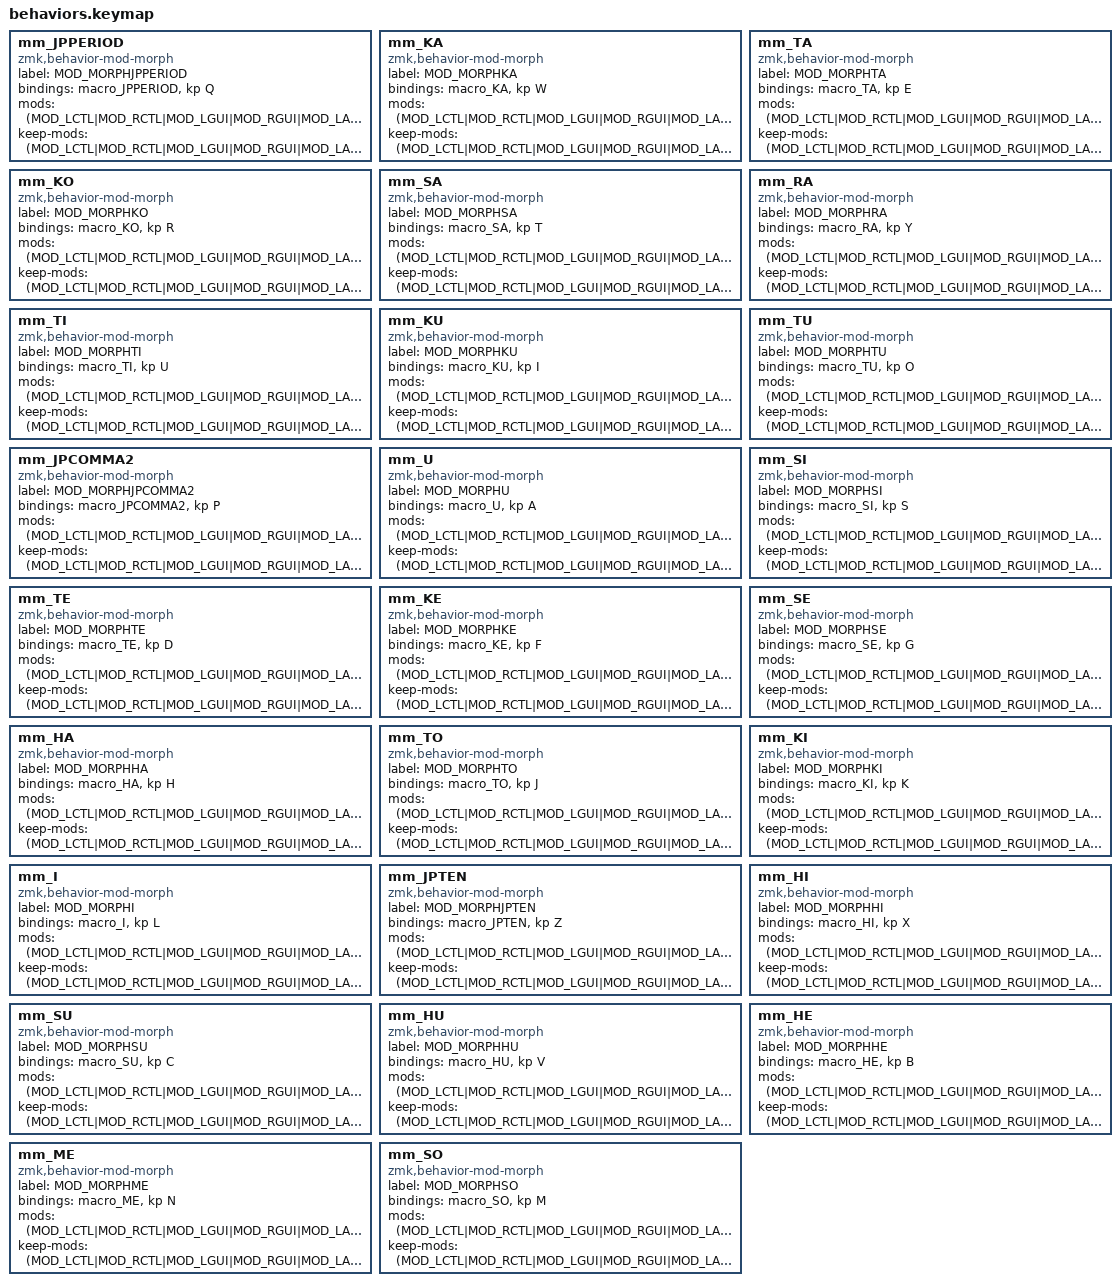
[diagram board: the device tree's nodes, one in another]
mm_JPPERIOD: mm_JPPERIOD{
compatible = "zmk,behavior-mod-morph";
label = "MOD_MORPHJPPERIOD";
#binding-cells = <0>;
bindings = <&macro_JPPERIOD>, <&kp Q>;
mods = <(MOD_LCTL|MOD_RCTL|MOD_LGUI|MOD_RGUI|MOD_LALT|MOD_RALT)>;
keep-mods = <(MOD_LCTL|MOD_RCTL|MOD_LGUI|MOD_RGUI|MOD_LALT)>;
};

mm_KA: mm_KA{
compatible = "zmk,behavior-mod-morph";
label = "MOD_MORPHKA";
#binding-cells = <0>;
bindings = <&macro_KA>, <&kp W>;
mods = <(MOD_LCTL|MOD_RCTL|MOD_LGUI|MOD_RGUI|MOD_LALT|MOD_RALT)>;
keep-mods = <(MOD_LCTL|MOD_RCTL|MOD_LGUI|MOD_RGUI|MOD_LALT)>;
};

mm_TA: mm_TA{
compatible = "zmk,behavior-mod-morph";
label = "MOD_MORPHTA";
#binding-cells = <0>;
bindings = <&macro_TA>, <&kp E>;
mods = <(MOD_LCTL|MOD_RCTL|MOD_LGUI|MOD_RGUI|MOD_LALT|MOD_RALT)>;
keep-mods = <(MOD_LCTL|MOD_RCTL|MOD_LGUI|MOD_RGUI|MOD_LALT)>;
};

mm_KO: mm_KO{
compatible = "zmk,behavior-mod-morph";
label = "MOD_MORPHKO";
#binding-cells = <0>;
bindings = <&macro_KO>, <&kp R>;
mods = <(MOD_LCTL|MOD_RCTL|MOD_LGUI|MOD_RGUI|MOD_LALT|MOD_RALT)>;
keep-mods = <(MOD_LCTL|MOD_RCTL|MOD_LGUI|MOD_RGUI|MOD_LALT)>;
};

mm_SA: mm_SA{
compatible = "zmk,behavior-mod-morph";
label = "MOD_MORPHSA";
#binding-cells = <0>;
bindings = <&macro_SA>, <&kp T>;
mods = <(MOD_LCTL|MOD_RCTL|MOD_LGUI|MOD_RGUI|MOD_LALT|MOD_RALT)>;
keep-mods = <(MOD_LCTL|MOD_RCTL|MOD_LGUI|MOD_RGUI|MOD_LALT)>;
};

mm_RA: mm_RA{
compatible = "zmk,behavior-mod-morph";
label = "MOD_MORPHRA";
#binding-cells = <0>;
bindings = <&macro_RA>, <&kp Y>;
mods = <(MOD_LCTL|MOD_RCTL|MOD_LGUI|MOD_RGUI|MOD_LALT|MOD_RALT)>;
keep-mods = <(MOD_LCTL|MOD_RCTL|MOD_LGUI|MOD_RGUI|MOD_LALT)>;
};

mm_TI: mm_TI{
compatible = "zmk,behavior-mod-morph";
label = "MOD_MORPHTI";
#binding-cells = <0>;
bindings = <&macro_TI>, <&kp U>;
mods = <(MOD_LCTL|MOD_RCTL|MOD_LGUI|MOD_RGUI|MOD_LALT|MOD_RALT)>;
keep-mods = <(MOD_LCTL|MOD_RCTL|MOD_LGUI|MOD_RGUI|MOD_LALT)>;
};

mm_KU: mm_KU{
compatible = "zmk,behavior-mod-morph";
label = "MOD_MORPHKU";
#binding-cells = <0>;
bindings = <&macro_KU>, <&kp I>;
mods = <(MOD_LCTL|MOD_RCTL|MOD_LGUI|MOD_RGUI|MOD_LALT|MOD_RALT)>;
keep-mods = <(MOD_LCTL|MOD_RCTL|MOD_LGUI|MOD_RGUI|MOD_LALT)>;
};

mm_TU: mm_TU{
compatible = "zmk,behavior-mod-morph";
label = "MOD_MORPHTU";
#binding-cells = <0>;
bindings = <&macro_TU>, <&kp O>;
mods = <(MOD_LCTL|MOD_RCTL|MOD_LGUI|MOD_RGUI|MOD_LALT|MOD_RALT)>;
keep-mods = <(MOD_LCTL|MOD_RCTL|MOD_LGUI|MOD_RGUI|MOD_LALT)>;
};

mm_JPCOMMA2: mm_JPCOMMA2{
compatible = "zmk,behavior-mod-morph";
label = "MOD_MORPHJPCOMMA2";
#binding-cells = <0>;
bindings = <&macro_JPCOMMA2>, <&kp P>;
mods = <(MOD_LCTL|MOD_RCTL|MOD_LGUI|MOD_RGUI|MOD_LALT|MOD_RALT)>;
keep-mods = <(MOD_LCTL|MOD_RCTL|MOD_LGUI|MOD_RGUI|MOD_LALT)>;
};

mm_U: mm_U{
compatible = "zmk,behavior-mod-morph";
label = "MOD_MORPHU";
#binding-cells = <0>;
bindings = <&macro_U>, <&kp A>;
mods = <(MOD_LCTL|MOD_RCTL|MOD_LGUI|MOD_RGUI|MOD_LALT|MOD_RALT)>;
keep-mods = <(MOD_LCTL|MOD_RCTL|MOD_LGUI|MOD_RGUI|MOD_LALT)>;
};

mm_SI: mm_SI{
compatible = "zmk,behavior-mod-morph";
label = "MOD_MORPHSI";
#binding-cells = <0>;
bindings = <&macro_SI>, <&kp S>;
mods = <(MOD_LCTL|MOD_RCTL|MOD_LGUI|MOD_RGUI|MOD_LALT|MOD_RALT)>;
keep-mods = <(MOD_LCTL|MOD_RCTL|MOD_LGUI|MOD_RGUI|MOD_LALT)>;
};

mm_TE: mm_TE{
compatible = "zmk,behavior-mod-morph";
label = "MOD_MORPHTE";
#binding-cells = <0>;
bindings = <&macro_TE>, <&kp D>;
mods = <(MOD_LCTL|MOD_RCTL|MOD_LGUI|MOD_RGUI|MOD_LALT|MOD_RALT)>;
keep-mods = <(MOD_LCTL|MOD_RCTL|MOD_LGUI|MOD_RGUI|MOD_LALT)>;
};

mm_KE: mm_KE{
compatible = "zmk,behavior-mod-morph";
label = "MOD_MORPHKE";
#binding-cells = <0>;
bindings = <&macro_KE>, <&kp F>;
mods = <(MOD_LCTL|MOD_RCTL|MOD_LGUI|MOD_RGUI|MOD_LALT|MOD_RALT)>;
keep-mods = <(MOD_LCTL|MOD_RCTL|MOD_LGUI|MOD_RGUI|MOD_LALT)>;
};

mm_SE: mm_SE{
compatible = "zmk,behavior-mod-morph";
label = "MOD_MORPHSE";
#binding-cells = <0>;
bindings = <&macro_SE>, <&kp G>;
mods = <(MOD_LCTL|MOD_RCTL|MOD_LGUI|MOD_RGUI|MOD_LALT|MOD_RALT)>;
keep-mods = <(MOD_LCTL|MOD_RCTL|MOD_LGUI|MOD_RGUI|MOD_LALT)>;
};

mm_HA: mm_HA{
compatible = "zmk,behavior-mod-morph";
label = "MOD_MORPHHA";
#binding-cells = <0>;
bindings = <&macro_HA>, <&kp H>;
mods = <(MOD_LCTL|MOD_RCTL|MOD_LGUI|MOD_RGUI|MOD_LALT|MOD_RALT)>;
keep-mods = <(MOD_LCTL|MOD_RCTL|MOD_LGUI|MOD_RGUI|MOD_LALT)>;
};

mm_TO: mm_TO{
compatible = "zmk,behavior-mod-morph";
label = "MOD_MORPHTO";
#binding-cells = <0>;
bindings = <&macro_TO>, <&kp J>;
mods = <(MOD_LCTL|MOD_RCTL|MOD_LGUI|MOD_RGUI|MOD_LALT|MOD_RALT)>;
keep-mods = <(MOD_LCTL|MOD_RCTL|MOD_LGUI|MOD_RGUI|MOD_LALT)>;
};

mm_KI: mm_KI{
compatible = "zmk,behavior-mod-morph";
label = "MOD_MORPHKI";
#binding-cells = <0>;
bindings = <&macro_KI>, <&kp K>;
mods = <(MOD_LCTL|MOD_RCTL|MOD_LGUI|MOD_RGUI|MOD_LALT|MOD_RALT)>;
keep-mods = <(MOD_LCTL|MOD_RCTL|MOD_LGUI|MOD_RGUI|MOD_LALT)>;
};

mm_I: mm_I{
compatible = "zmk,behavior-mod-morph";
label = "MOD_MORPHI";
#binding-cells = <0>;
bindings = <&macro_I>, <&kp L>;
mods = <(MOD_LCTL|MOD_RCTL|MOD_LGUI|MOD_RGUI|MOD_LALT|MOD_RALT)>;
keep-mods = <(MOD_LCTL|MOD_RCTL|MOD_LGUI|MOD_RGUI|MOD_LALT)>;
};

mm_JPTEN: mm_JPTEN{
compatible = "zmk,behavior-mod-morph";
label = "MOD_MORPHJPTEN";
#binding-cells = <0>;
bindings = <&macro_JPTEN>, <&kp Z>;
mods = <(MOD_LCTL|MOD_RCTL|MOD_LGUI|MOD_RGUI|MOD_LALT|MOD_RALT)>;
keep-mods = <(MOD_LCTL|MOD_RCTL|MOD_LGUI|MOD_RGUI|MOD_LALT)>;
};

mm_HI: mm_HI{
compatible = "zmk,behavior-mod-morph";
label = "MOD_MORPHHI";
#binding-cells = <0>;
bindings = <&macro_HI>, <&kp X>;
mods = <(MOD_LCTL|MOD_RCTL|MOD_LGUI|MOD_RGUI|MOD_LALT|MOD_RALT)>;
keep-mods = <(MOD_LCTL|MOD_RCTL|MOD_LGUI|MOD_RGUI|MOD_LALT)>;
};

mm_SU: mm_SU{
compatible = "zmk,behavior-mod-morph";
label = "MOD_MORPHSU";
#binding-cells = <0>;
bindings = <&macro_SU>, <&kp C>;
mods = <(MOD_LCTL|MOD_RCTL|MOD_LGUI|MOD_RGUI|MOD_LALT|MOD_RALT)>;
keep-mods = <(MOD_LCTL|MOD_RCTL|MOD_LGUI|MOD_RGUI|MOD_LALT)>;
};

mm_HU: mm_HU{
compatible = "zmk,behavior-mod-morph";
label = "MOD_MORPHHU";
#binding-cells = <0>;
bindings = <&macro_HU>, <&kp V>;
mods = <(MOD_LCTL|MOD_RCTL|MOD_LGUI|MOD_RGUI|MOD_LALT|MOD_RALT)>;
keep-mods = <(MOD_LCTL|MOD_RCTL|MOD_LGUI|MOD_RGUI|MOD_LALT)>;
};

mm_HE: mm_HE{
compatible = "zmk,behavior-mod-morph";
label = "MOD_MORPHHE";
#binding-cells = <0>;
bindings = <&macro_HE>, <&kp B>;
mods = <(MOD_LCTL|MOD_RCTL|MOD_LGUI|MOD_RGUI|MOD_LALT|MOD_RALT)>;
keep-mods = <(MOD_LCTL|MOD_RCTL|MOD_LGUI|MOD_RGUI|MOD_LALT)>;
};

mm_ME: mm_ME{
compatible = "zmk,behavior-mod-morph";
label = "MOD_MORPHME";
#binding-cells = <0>;
bindings = <&macro_ME>, <&kp N>;
mods = <(MOD_LCTL|MOD_RCTL|MOD_LGUI|MOD_RGUI|MOD_LALT|MOD_RALT)>;
keep-mods = <(MOD_LCTL|MOD_RCTL|MOD_LGUI|MOD_RGUI|MOD_LALT)>;
};

mm_SO: mm_SO{
compatible = "zmk,behavior-mod-morph";
label = "MOD_MORPHSO";
#binding-cells = <0>;
bindings = <&macro_SO>, <&kp M>;
mods = <(MOD_LCTL|MOD_RCTL|MOD_LGUI|MOD_RGUI|MOD_LALT|MOD_RALT)>;
keep-mods = <(MOD_LCTL|MOD_RCTL|MOD_LGUI|MOD_RGUI|MOD_LALT)>;
};

